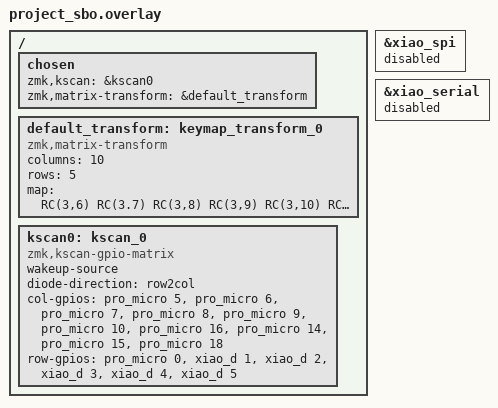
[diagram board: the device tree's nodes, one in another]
/*
 * Copyright (c) 2022 The ZMK Contributors
 *
 * SPDX-License-Identifier: MIT
 */

#include <dt-bindings/zmk/matrix_transform.h>

/ {
    chosen {
        zmk,kscan = &kscan0;
        zmk,matrix-transform = &default_transform;
    /delete-property/ zephyr,console;
    /delete-property/ zephyr,shell-uart;
    };

    default_transform: keymap_transform_0 {
        compatible = "zmk,matrix-transform";
        columns = <10>;
        rows = <5>;
        map = <
            RC(3,6) RC(3.7) RC(3,8) RC(3,9) RC(3,10) RC(3,16) RC(3,14) RC(3,15)
            RC(2,6) RC(2,7) RC(2,8) RC(2,9) RC(2,10) RC(2,16) RC(2,14) RC(2,15)
    RC(0,5) RC(0,6) RC(0,7) RC(0,8) RC(0,9) RC(0,10) RC(0,16) RC(0,14) RC(0,15) RC(0,18)
    RC(1,5) RC(1,6) RC(1,7) RC(1,8) RC(1,9) RC(1,10) RC(1,16) RC(1,14) RC(1,15) RC(1,18)
                            RC(4,8) RC(4,9) RC(4,10) RC(4,16)
        >;
    };


    kscan0: kscan_0 {
        compatible = "zmk,kscan-gpio-matrix";
        wakeup-source;

        diode-direction = "row2col";

        col-gpios
            = <&pro_micro 5 (GPIO_ACTIVE_HIGH | GPIO_PULL_DOWN)>
            , <&pro_micro 6 (GPIO_ACTIVE_HIGH | GPIO_PULL_DOWN)>
            , <&pro_micro 7 (GPIO_ACTIVE_HIGH | GPIO_PULL_DOWN)>
            , <&pro_micro 8 (GPIO_ACTIVE_HIGH | GPIO_PULL_DOWN)>
            , <&pro_micro 9 (GPIO_ACTIVE_HIGH | GPIO_PULL_DOWN)>
            , <&pro_micro 10 (GPIO_ACTIVE_HIGH | GPIO_PULL_DOWN)>
            , <&pro_micro 16 (GPIO_ACTIVE_HIGH | GPIO_PULL_DOWN)>
            , <&pro_micro 14 (GPIO_ACTIVE_HIGH | GPIO_PULL_DOWN)>
            , <&pro_micro 15 (GPIO_ACTIVE_HIGH | GPIO_PULL_DOWN)>
            , <&pro_micro 18 (GPIO_ACTIVE_HIGH | GPIO_PULL_DOWN)>
            ;

        row-gpios
            = <&pro_micro 0 GPIO_ACTIVE_HIGH>
            , <&xiao_d 1 GPIO_ACTIVE_HIGH>
            , <&xiao_d 2 GPIO_ACTIVE_HIGH>
            , <&xiao_d 3 GPIO_ACTIVE_HIGH>
            , <&xiao_d 4 GPIO_ACTIVE_HIGH>
            , <&xiao_d 5 GPIO_ACTIVE_HIGH>
            ;
    };

};

&xiao_spi { status = "disabled"; };
&xiao_serial { status = "disabled"; };
